# PIC32MX664F064L register map
Vendor: Microchip
Registers are 32-bit, read-write, reset 0x0 unless marked. A register's access mark holds for its fields unless they carry their own. Addresses are absolute, and some are shared; only a register's first bit layout is shown; [hi:lo] are bit positions; {n}, {i} and the like mark numbered series.

## DMAC2
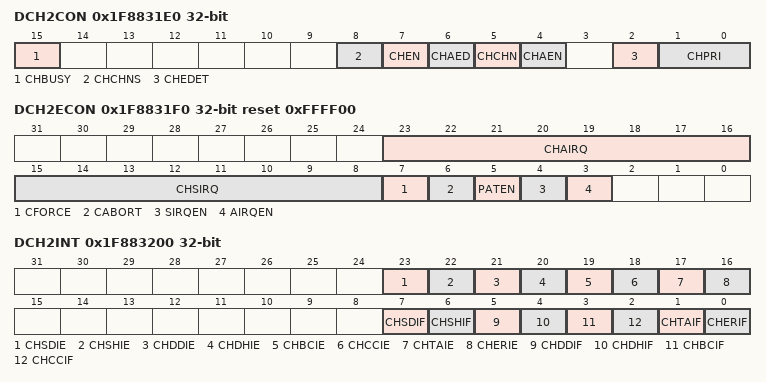
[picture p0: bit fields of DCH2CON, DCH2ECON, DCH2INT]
0x1F8831E0 DCH2CON reset not defined — (power-on value ----------------x------00000-000)
  [15] CHBUSY, [8] CHCHNS, [7] CHEN, [6] CHAED, [5] CHCHN, [4] CHAEN, [2] CHEDET ro, [1:0] CHPRI
0x1F8831F0 DCH2ECON reset 0xFFFF00
  [23:16] CHAIRQ
  [15:8] CHSIRQ
  [7] CFORCE — (can only be set)
  [6] CABORT — (can only be set)
  [5] PATEN
  [4] SIRQEN
  [3] AIRQEN
0x1F883200 DCH2INT
  [23] CHSDIE, [22] CHSHIE, [21] CHDDIE, [20] CHDHIE, [19] CHBCIE, [18] CHCCIE, [17] CHTAIE, [16] CHERIE, [7] CHSDIF, [6] CHSHIF, [5] CHDDIF, [4] CHDHIF, [3] CHBCIF, [2] CHCCIF, [1] CHTAIF, [0] CHERIF
0x1F883210 DCH2SSA reset not defined — (power-on value xxxxxxxxxxxxxxxxxxxxxxxxxxxxxxxx)
0x1F883220 DCH2DSA reset not defined — (power-on value xxxxxxxxxxxxxxxxxxxxxxxxxxxxxxxx)
0x1F883230 DCH2SSIZ reset not defined — (power-on value ----------------xxxxxxxxxxxxxxxx)
  [15:0] CHSSIZ
0x1F883240 DCH2DSIZ reset not defined — (power-on value ----------------xxxxxxxxxxxxxxxx)
  [15:0] CHDSIZ
0x1F883250 DCH2SPTR reset not defined — (power-on value ----------------xxxxxxxxxxxxxxxx)
  [15:0] CHSPTR
0x1F883260 DCH2DPTR ro
  [15:0] CHDPTR
0x1F883270 DCH2CSIZ reset not defined — (power-on value ----------------xxxxxxxxxxxxxxxx)
  [15:0] CHCSIZ
0x1F883280 DCH2CPTR reset not defined — (power-on value ----------------xxxxxxxxxxxxxxxx)
  [15:0] CHCPTR
0x1F883290 DCH2DAT reset not defined — (power-on value ------------------------xxxxxxxx)
  [7:0] DCHPDAT

## DMAC3
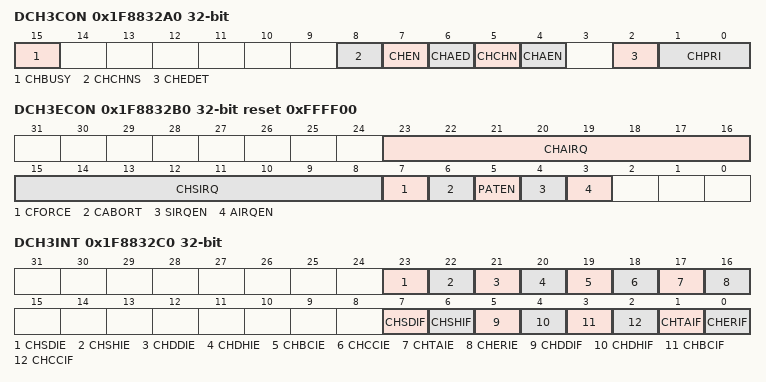
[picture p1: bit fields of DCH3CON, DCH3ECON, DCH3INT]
0x1F8832A0 DCH3CON reset not defined — (power-on value ----------------x------00000-000)
  [15] CHBUSY, [8] CHCHNS, [7] CHEN, [6] CHAED, [5] CHCHN, [4] CHAEN, [2] CHEDET ro, [1:0] CHPRI
0x1F8832B0 DCH3ECON reset 0xFFFF00
  [23:16] CHAIRQ
  [15:8] CHSIRQ
  [7] CFORCE — (can only be set)
  [6] CABORT — (can only be set)
  [5] PATEN
  [4] SIRQEN
  [3] AIRQEN
0x1F8832C0 DCH3INT
  [23] CHSDIE, [22] CHSHIE, [21] CHDDIE, [20] CHDHIE, [19] CHBCIE, [18] CHCCIE, [17] CHTAIE, [16] CHERIE, [7] CHSDIF, [6] CHSHIF, [5] CHDDIF, [4] CHDHIF, [3] CHBCIF, [2] CHCCIF, [1] CHTAIF, [0] CHERIF
0x1F8832D0 DCH3SSA reset not defined — (power-on value xxxxxxxxxxxxxxxxxxxxxxxxxxxxxxxx)
0x1F8832E0 DCH3DSA reset not defined — (power-on value xxxxxxxxxxxxxxxxxxxxxxxxxxxxxxxx)
0x1F8832F0 DCH3SSIZ reset not defined — (power-on value ----------------xxxxxxxxxxxxxxxx)
  [15:0] CHSSIZ
0x1F883300 DCH3DSIZ reset not defined — (power-on value ----------------xxxxxxxxxxxxxxxx)
  [15:0] CHDSIZ
0x1F883310 DCH3SPTR reset not defined — (power-on value ----------------xxxxxxxxxxxxxxxx)
  [15:0] CHSPTR
0x1F883320 DCH3DPTR ro
  [15:0] CHDPTR
0x1F883330 DCH3CSIZ reset not defined — (power-on value ----------------xxxxxxxxxxxxxxxx)
  [15:0] CHCSIZ
0x1F883340 DCH3CPTR reset not defined — (power-on value ----------------xxxxxxxxxxxxxxxx)
  [15:0] CHCPTR
0x1F883350 DCH3DAT reset not defined — (power-on value ------------------------xxxxxxxx)
  [7:0] DCHPDAT

## PCACHE
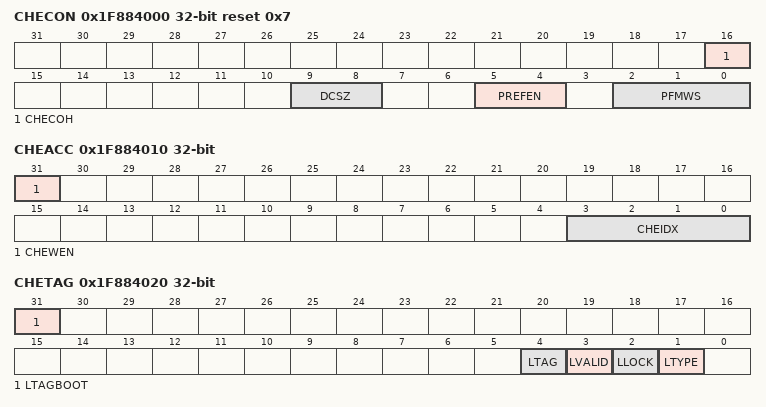
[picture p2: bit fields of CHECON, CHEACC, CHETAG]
0x1F884000 CHECON reset 0x7
  [16] CHECOH, [9:8] DCSZ, [5:4] PREFEN, [2:0] PFMWS
0x1F884010 CHEACC
  [31] CHEWEN, [3:0] CHEIDX
0x1F884020 CHETAG reset not defined — (power-on value 0xxxxxxxxxxxxxxxxxxxxxxxxxxx0010)
  [31] LTAGBOOT, [4] LTAG, [3] LVALID, [2] LLOCK, [1] LTYPE
0x1F884030 CHEMSK
  [15:5] LMASK
{0x1F884040+0x10*i} CHEW{i} reset not defined (i=0..3) — (power-on value xxxxxxxxxxxxxxxxxxxxxxxxxxxxxxxx)
0x1F884080 CHELRU
  [24:0] CHELRU
0x1F884090 CHEHIT reset not defined — (power-on value xxxxxxxxxxxxxxxxxxxxxxxxxxxxxxxx)
  [31:0] CHEHIT — (can only be cleared)
0x1F8840A0 CHEMIS reset not defined — (power-on value xxxxxxxxxxxxxxxxxxxxxxxxxxxxxxxx)
  [31:0] CHEMIS — (can only be cleared)
0x1F8840C0 CHEPFABT reset not defined — (power-on value xxxxxxxxxxxxxxxxxxxxxxxxxxxxxxxx)
  [31:0] CHEPFABT — (can only be cleared)
